# RP2350 register map
Vendor: Raspberry Pi; Series: RP; File version: 0.1
CPU: CM33 r1p0, little endian, MPU, FPU, DSP, VTOR, 4 interrupt priority bits, 52 interrupts, 8 SAU regions
Registers are 32-bit, read-write, reset 0x0 unless marked. A register's access mark holds for its fields unless they carry their own. Offsets are from the block's base; [hi:lo] are bit positions; {n}, {i} and the like mark numbered series.

## ROSC — Peripheral description
Base 0x400E8000
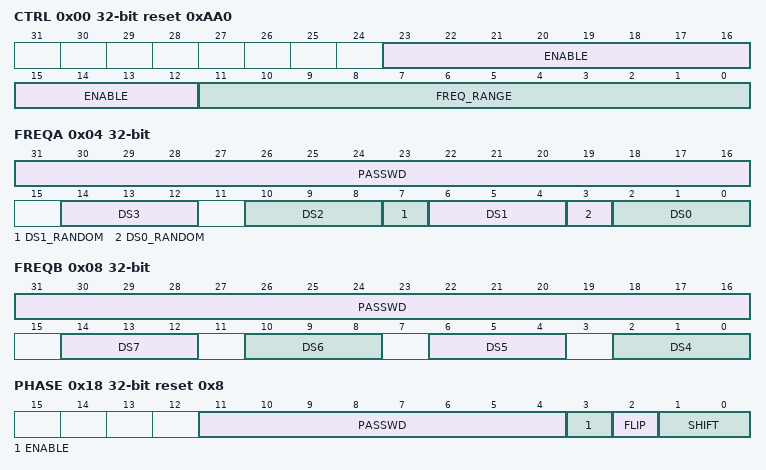
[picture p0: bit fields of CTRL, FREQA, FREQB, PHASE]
0x00 CTRL reset 0xAA0 — Ring Oscillator control
  [23:12] ENABLE — On power-up this field is initialised to ENABLE The system clock must be switched to another source before setting this field to DISABLE otherwise the chip will lock up The 12-bit code is intended to give some protection against accidental writes. An invalid setting will enable the oscillator.
    0xD1E=DISABLE; 0xFAB=ENABLE
  [11:0] FREQ_RANGE — Controls the number of delay stages in the ROSC ring LOW uses stages 0 to 7 MEDIUM uses stages 2 to 7 HIGH uses stages 4 to 7 TOOHIGH uses stages 6 to 7 and should not be used because its frequency exceeds design specifications The clock output will not glitch when changing the range up one step at a time The clock output will glitch when changing the range down Note: the values here are gray coded which is why HIGH comes before TOOHIGH
    0xFA4=LOW; 0xFA5=MEDIUM; 0xFA7=HIGH; 0xFA6=TOOHIGH
0x04 FREQA — The FREQA & FREQB registers control the frequency by controlling the drive strength of each stage The drive strength has 4 levels determined by the number of bits set Increasing the number of bits set increases the drive strength and increases the oscillation frequency 0 bits set is the default drive strength 1 bit set doubles the drive strength 2 bits set triples drive strength 3 bits set quadruples drive strength For frequency randomisation set both DS0_RANDOM=1 & DS1_RANDOM=1
  [31:16] PASSWD — Set to 0x9696 to apply the settings Any other value in this field will set all drive strengths to 0
    0x9696=PASS
  [4n+2:4n] DS{n} (n=0..3) — Stage {n} drive strength
  [7] DS1_RANDOM — Randomises the stage 1 drive strength
  [3] DS0_RANDOM — Randomises the stage 0 drive strength
0x08 FREQB — For a detailed description see freqa register
  [31:16] PASSWD — Set to 0x9696 to apply the settings Any other value in this field will set all drive strengths to 0
    0x9696=PASS
  [4n-14:4n-16] DS{n} (n=4..7) — Stage {n} drive strength
0x0C RANDOM reset 0x3F04B16D — Loads a value to the LFSR randomiser
  [31:0] SEED — Pre-defined description
0x10 DORMANT reset not defined — Ring Oscillator pause control
  [31:0] DORMANT — This is used to save power by pausing the ROSC On power-up this field is initialised to WAKE An invalid write will also select WAKE Warning: setup the irq before selecting dormant mode
    0x636F6D61=dormant; 0x77616B65=WAKE
0x14 DIV reset not defined — Controls the output divider
  [15:0] DIV — set to 0xaa00 + div where div = 0 divides by 128 div = 1-127 divides by div any other value sets div=128 this register resets to div=32
    0xAA00=PASS
0x18 PHASE reset 0x8 — Controls the phase shifted output
  [11:4] PASSWD — set to 0xaa any other value enables the output with shift=0
  [3] ENABLE — enable the phase-shifted output this can be changed on-the-fly
  [2] FLIP — invert the phase-shifted output this is ignored when div=1
  [1:0] SHIFT — phase shift the phase-shifted output by SHIFT input clocks this can be changed on-the-fly must be set to 0 before setting div=1
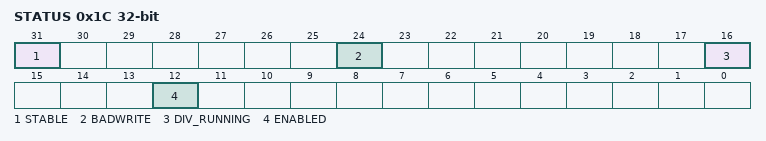
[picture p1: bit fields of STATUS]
0x1C STATUS — Ring Oscillator Status
  [31] STABLE ro — Oscillator is running and stable
  [24] BADWRITE write-1-clears — An invalid value has been written to CTRL_ENABLE or CTRL_FREQ_RANGE or FREQA or FREQB or DIV or PHASE or DORMANT
  [16] DIV_RUNNING ro — post-divider is running this resets to 0 but transitions to 1 during chip startup
  [12] ENABLED ro — Oscillator is enabled but not necessarily running and stable this resets to 0 but transitions to 1 during chip startup
0x20 RANDOMBIT reset 0x1 — This just reads the state of the oscillator output so randomness is compromised if the ring oscillator is stopped or run at a harmonic of the bus frequency
  [0] RANDOMBIT ro — Pre-defined description
0x24 COUNT — A down counter running at the ROSC frequency which counts to zero and stops. To start the counter write a non-zero value. Can be used for short software pauses when setting up time sensitive hardware.
  [15:0] COUNT — Pre-defined description
